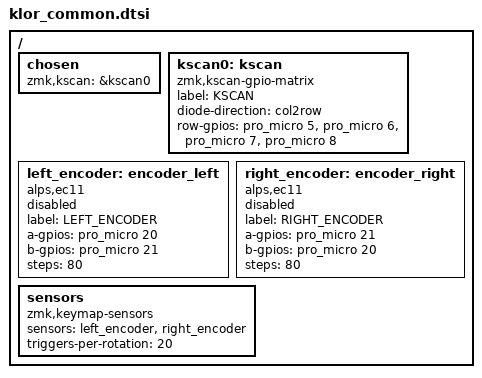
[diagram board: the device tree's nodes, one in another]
/*
 * Copyright (c) 2022 The ZMK Contributors
 *
 * SPDX-License-Identifier: MIT
 */

#include "klor.dtsi"

/ {
	chosen {
		zmk,kscan = &kscan0;
	};

	kscan0: kscan {
		compatible = "zmk,kscan-gpio-matrix";
		label = "KSCAN";

		diode-direction = "col2row";
		row-gpios
			= <&pro_micro 5 (GPIO_ACTIVE_HIGH | GPIO_PULL_DOWN)>
			, <&pro_micro 6 (GPIO_ACTIVE_HIGH | GPIO_PULL_DOWN)>
			, <&pro_micro 7 (GPIO_ACTIVE_HIGH | GPIO_PULL_DOWN)>
			, <&pro_micro 8 (GPIO_ACTIVE_HIGH | GPIO_PULL_DOWN)>
			;
	};

	left_encoder: encoder_left {
		compatible = "alps,ec11";
		label = "LEFT_ENCODER";
		a-gpios = <&pro_micro 20 (GPIO_ACTIVE_HIGH | GPIO_PULL_UP)>;
		b-gpios = <&pro_micro 21 (GPIO_ACTIVE_HIGH | GPIO_PULL_UP)>;
		steps = <80>;
		status = "disabled";
	};

	right_encoder: encoder_right {
		compatible = "alps,ec11";
		label = "RIGHT_ENCODER";
		a-gpios = <&pro_micro 21 (GPIO_ACTIVE_HIGH | GPIO_PULL_UP)>;
		b-gpios = <&pro_micro 20 (GPIO_ACTIVE_HIGH | GPIO_PULL_UP)>;
		steps = <80>;
		status = "disabled";
	};

	sensors: sensors {
		compatible = "zmk,keymap-sensors";
		sensors = <&left_encoder &right_encoder>;
		triggers-per-rotation = <20>;
	};

	// TODO: RGB node(s)
};
